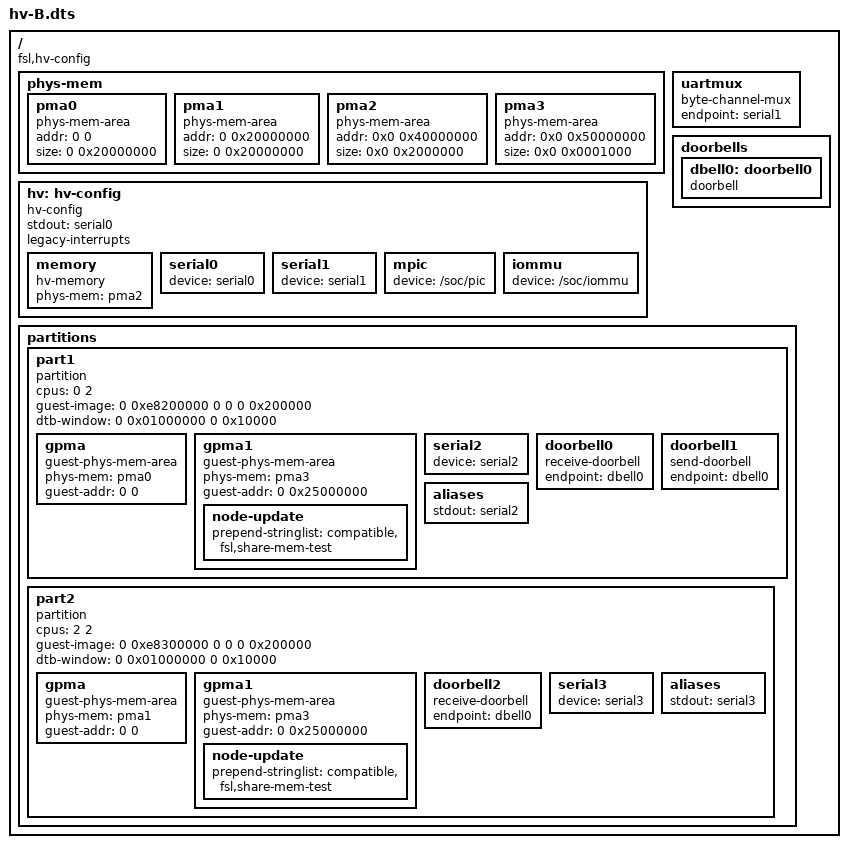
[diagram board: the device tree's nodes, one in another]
/dts-v1/;

/ {
	compatible = "fsl,hv-config";

	phys-mem {
		pma0: pma0 {
			compatible = "phys-mem-area";
			addr = <0 0>;
			size = <0 0x20000000>;
		};

		pma1: pma1 {
			compatible = "phys-mem-area";
			addr = <0 0x20000000>;
			size = <0 0x20000000>;
		};

		pma2: pma2 {
			compatible = "phys-mem-area";
			addr = <0x0 0x40000000>;
			size = <0x0 0x2000000>;
		};

		pma3: pma3 {
			compatible = "phys-mem-area";
			addr = <0x0 0x50000000>;
			size = <0x0 0x0001000>;
		};

	};

	hv: hv-config {
		compatible = "hv-config";
		stdout = <&serial0>;
		legacy-interrupts;

		memory {
			compatible = "hv-memory";
			phys-mem = <&pma2>;
		};

		serial0: serial0 {
			// Hypervisor console
			device = "serial0";
		};

		serial1: serial1 {
			// Byte channel
			device = "serial1";
		};

		mpic {
			device = "/soc/pic";
		};

		iommu {
			device = "/soc/iommu";
		};
	};

	uartmux: uartmux {
		compatible = "byte-channel-mux";
		endpoint = <&serial1>;
	};

	doorbells {
		dbell0: doorbell0 {
			compatible = "doorbell";
		};
	};

	partitions {
		part1 {
			compatible = "partition";
			cpus = <0 2>;
			guest-image = <0 0xe8200000 0 0 0 0x200000>;
			dtb-window = <0 0x01000000 0 0x10000>;

			gpma {
				compatible = "guest-phys-mem-area";
				phys-mem = <&pma0>;
				guest-addr = <0 0>;
			};

			gpma1 {
				compatible = "guest-phys-mem-area";
				phys-mem = <&pma3>;
				guest-addr = <0 0x25000000>;
				node-update {
					prepend-stringlist = "compatible", "fsl,share-mem-test";
				};
			};

			serial2: serial2 {
				device = "serial2";
			};

			doorbell0 {
				compatible = "receive-doorbell";
				endpoint = <&dbell0>;
			};

			doorbell1 {
				compatible = "send-doorbell";
				endpoint = <&dbell0>;
			};

			aliases {
				stdout = <&serial2>;
			};
		};
		part2 {
			compatible = "partition";
			cpus = <2 2>;
			guest-image = <0 0xe8300000 0 0 0 0x200000>;
			dtb-window = <0 0x01000000 0 0x10000>;

			gpma {
				compatible = "guest-phys-mem-area";
				phys-mem = <&pma1>;
				guest-addr = <0 0>;
			};

			gpma1 {
				compatible = "guest-phys-mem-area";
				phys-mem = <&pma3>;
				guest-addr = <0 0x25000000>;
				node-update {
					prepend-stringlist = "compatible", "fsl,share-mem-test";
				};
			};

			doorbell2 {
				compatible = "receive-doorbell";
				endpoint = <&dbell0>;
			};

			serial3: serial3 {
				device = "serial3";
			};

			aliases {
				stdout = <&serial3>;
			};
		};
	};
};
